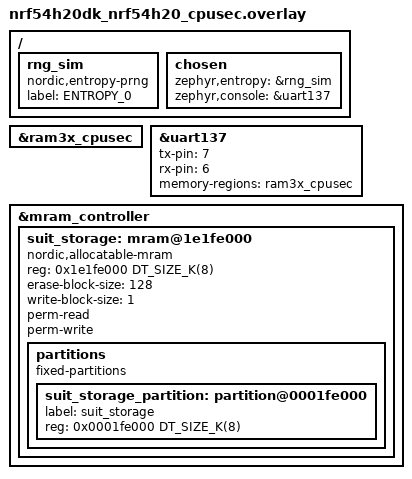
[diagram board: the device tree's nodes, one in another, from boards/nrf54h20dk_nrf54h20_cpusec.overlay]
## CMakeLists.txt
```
#
# Copyright (c) 2022 Nordic Semiconductor ASA
#
# SPDX-License-Identifier: Apache-2.0
#

cmake_minimum_required(VERSION 3.20.0)

find_package(Zephyr REQUIRED HINTS $ENV{ZEPHYR_BASE})

project(integration_test_suit_storage)
include(../cmake/test_template.cmake)

# Link with the CMake target, that includes SUIT platform internal APIs header
zephyr_library_link_libraries(suit_common)
```

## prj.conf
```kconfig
#
# Copyright (c) 2022 Nordic Semiconductor ASA
#
# SPDX-License-Identifier: Apache-2.0
#

CONFIG_ZTEST=y
CONFIG_SUIT=y
CONFIG_FLASH=y
CONFIG_SUIT_COMPONENT_MRAM=y
# It is required to reserve at least SUIT_PARTITION_ENVELOPE_SIZE
# on the stack for the test execution.
CONFIG_ZTEST_STACK_SIZE=4096
CONFIG_SUIT_PARTITION_N_ENVELOPES=3
```

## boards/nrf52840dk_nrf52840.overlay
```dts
/*
 * Copyright (c) 2022 Nordic Semiconductor ASA
 *
 * SPDX-License-Identifier: LicenseRef-Nordic-4-Clause
 */

 &flash0 {
	partitions {
		compatible = "fixed-partitions";
		#address-cells = <1>;
		#size-cells = <1>;

		/* Use the last 16KB of NVM as suit storage. */
		suit_storage_partition: partition@000fc000 {
			label = "suit_storage";
			reg = <0x000fc000 DT_SIZE_K(16)>;
		};
	};
};
```

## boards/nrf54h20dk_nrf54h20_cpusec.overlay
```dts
/*
 * Copyright (c) 2022 Nordic Semiconductor ASA
 *
 * SPDX-License-Identifier: LicenseRef-Nordic-5-Clause
 */

/ {
	rng_sim: rng_sim {
		status = "okay";
		compatible = "nordic,entropy-prng";
		label = "ENTROPY_0";
	};

	chosen {
		zephyr,entropy = &rng_sim;
		zephyr,console = &uart137;
	};
};

&ram3x_cpusec {
	status = "okay";
};

&uart137 {
	status = "okay";
	tx-pin = <7>;
	rx-pin = <6>;
	memory-regions = <&ram3x_cpusec>;
};

&mram_controller {
	suit_storage: mram@1e1fe000 {
		compatible = "nordic,allocatable-mram", "soc-nv-flash";
		reg = <0x1e1fe000 DT_SIZE_K(8)>;
		erase-block-size = <128>;
		write-block-size = <1>;
		perm-read;
		perm-write;
		partitions {
			compatible = "fixed-partitions";
			#address-cells = <1>;
			#size-cells = <1>;

			/* Use the last 8KB of NVM as suit storage. */
			suit_storage_partition: partition@0001fe000 {
				label = "suit_storage";
				reg = <0x0001fe000 DT_SIZE_K(8)>;
			};
		};
	};
};
```

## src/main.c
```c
/*
 * Copyright (c) 2022 Nordic Semiconductor ASA
 *
 * SPDX-License-Identifier: Apache-2.0
 */

#include <ztest.h>
#include <suit_storage.h>
#include <drivers/flash.h>
#include <zephyr/storage/flash_map.h>
#ifdef CONFIG_FLASH_SIMULATOR
#include <zephyr/drivers/flash/flash_simulator.h>
#endif /* CONFIG_FLASH_SIMULATOR */

/* Calculate absolute address from flash offset. */
#ifdef CONFIG_FLASH_SIMULATOR
static uint8_t *f_base_address = NULL;
#define FLASH_ADDRESS(address)  (f_base_address + address)
#else /* CONFIG_FLASH_SIMULATOR */
#define FLASH_ADDRESS(address)  (COND_CODE_1(DT_NODE_EXISTS(DT_NODELABEL(mram10)), \
	((address) + (DT_REG_ADDR(DT_NODELABEL(mram10)) & 0xEFFFFFFFUL)), \
	(address)))
#endif /* CONFIG_FLASH_SIMULATOR */

#define SUIT_STORAGE_ADDRESS     FLASH_ADDRESS(SUIT_STORAGE_OFFSET)
#define SUIT_STORAGE_OFFSET      FLASH_AREA_OFFSET(suit_storage)
#define SUIT_STORAGE_SIZE        FLASH_AREA_SIZE(suit_storage)

#define UPDATE_MAGIC_VALUE_AVAILABLE 0x5555AAAA
#define UPDATE_MAGIC_VALUE_CLEARED   0xAAAA5555
#define UPDATE_MAGIC_VALUE_EMPTY     0xFFFFFFFF

#define zassert_area_empty() \
	zassert_equal(*((uint32_t *)SUIT_STORAGE_ADDRESS), UPDATE_MAGIC_VALUE_EMPTY, \
		"Test precondition not met: area is not empty (0x%x).", \
		*((uint32_t *)SUIT_STORAGE_ADDRESS));

#define zassert_area_cleared() \
	zassert_equal(*((uint32_t *)SUIT_STORAGE_ADDRESS), UPDATE_MAGIC_VALUE_CLEARED, \
		"Test precondition not met: area is not cleared (0x%x).", \
		*((uint32_t *)SUIT_STORAGE_ADDRESS));

#define zassert_area_update_available() \
	zassert_equal(*((uint32_t *)SUIT_STORAGE_ADDRESS), UPDATE_MAGIC_VALUE_AVAILABLE, \
		"Test precondition not met: update is not available (0x%x).", \
		*((uint32_t *)SUIT_STORAGE_ADDRESS));


/** @brief SUIT envelope generated using the manifest/sample.json input file.
 *
 * @details This envelope contains 256-byte random numbers attached as an integrated
 *          payload and fetched directly into the memory-mapped region during install step.
 *          The envelope has been signed using the manifest/key_private.pem key.
 *
 * @note Please use the manifest/reenerate.sh script for regenerating payloads.
 */
static uint8_t manifest_buf[] = {
	0xD8, 0x6B, 0xA4, 0x02, 0x58, 0x73, 0x82, 0x58, 0x24, 0x82, 0x2F, 0x58, 0x20, 0x60, 0xE2,
	0x47, 0x5D, 0x53, 0x4C, 0xCB, 0x8B, 0x0F, 0x7E, 0x0B, 0xC1, 0x3E, 0x96, 0xB2, 0x99, 0xD6,
	0xF8, 0x41, 0xB1, 0x1B, 0x61, 0xDF, 0x88, 0xF3, 0xC1, 0x88, 0xC2, 0xBD, 0x5C, 0xE5, 0xF6,
	0x58, 0x4A, 0xD2, 0x84, 0x43, 0xA1, 0x01, 0x26, 0xA0, 0xF6, 0x58, 0x40, 0x09, 0xDB, 0x59,
	0xBF, 0xA2, 0xB1, 0x1F, 0x72, 0x26, 0xC4, 0xB9, 0x6F, 0xBA, 0x1E, 0xB5, 0x3F, 0x84, 0x15,
	0xAA, 0x6E, 0x7A, 0xE3, 0xA3, 0x8D, 0x0E, 0xCB, 0x29, 0x8A, 0x52, 0x2E, 0x5C, 0x9F, 0x7B,
	0x60, 0xEA, 0xEA, 0xA3, 0xDA, 0xCC, 0xF9, 0xC3, 0xE7, 0x99, 0x5B, 0x43, 0xBF, 0xA8, 0x1E,
	0x74, 0x20, 0xCE, 0x73, 0x8E, 0x8E, 0x2B, 0xF0, 0x2C, 0x32, 0xD3, 0x33, 0x04, 0x5D, 0x04,
	0xA8, 0x03, 0x58, 0xB8, 0xA7, 0x01, 0x01, 0x02, 0x01, 0x03, 0x58, 0x6D, 0xA2, 0x02, 0x81,
	0x84, 0x41, 0x4D, 0x41, 0x02, 0x45, 0x1A, 0x0E, 0x05, 0x40, 0x00, 0x45, 0x1A, 0x00, 0x05,
	0x60, 0x00, 0x04, 0x58, 0x56, 0x86, 0x14, 0xA4, 0x01, 0x50, 0x2B, 0xDC, 0x1C, 0x07, 0xE0,
	0xD1, 0x54, 0x84, 0xBE, 0x50, 0x63, 0x17, 0x4D, 0x5A, 0x74, 0xC3, 0x02, 0x50, 0x85, 0x20,
	0xEA, 0x9C, 0x51, 0x5E, 0x57, 0x79, 0x8B, 0x5F, 0xBD, 0xAD, 0x67, 0xDE, 0xC7, 0xD9, 0x03,
	0x58, 0x24, 0x82, 0x2F, 0x58, 0x20, 0x5F, 0xC3, 0x54, 0xBF, 0x8E, 0x8C, 0x50, 0xFB, 0x4F,
	0xBC, 0x2C, 0xFA, 0xEB, 0x04, 0x53, 0x41, 0xC9, 0x80, 0x6D, 0xEA, 0xBD, 0xCB, 0x41, 0x54,
	0xFB, 0x79, 0xCC, 0xA4, 0xF0, 0xC9, 0x8C, 0x12, 0x0E, 0x19, 0x01, 0x00, 0x01, 0x0F, 0x02,
	0x0F, 0x07, 0x43, 0x82, 0x03, 0x0F, 0x09, 0x43, 0x82, 0x17, 0x02, 0x11, 0x52, 0x86, 0x14,
	0xA1, 0x15, 0x69, 0x23, 0x66, 0x69, 0x6C, 0x65, 0x2E, 0x62, 0x69, 0x6E, 0x15, 0x02, 0x03,
	0x0F, 0x17, 0x82, 0x2F, 0x58, 0x20, 0xD1, 0x7B, 0x63, 0xF9, 0x8E, 0x13, 0x94, 0x5A, 0x60,
	0xA3, 0xC3, 0x55, 0x9B, 0xE3, 0xAE, 0x33, 0xF5, 0xF4, 0xA2, 0x0B, 0x7A, 0x23, 0x10, 0xA1,
	0x5C, 0x3A, 0xC9, 0xEC, 0xD9, 0xBD, 0x0D, 0xC7, 0x17, 0x58, 0x91, 0xA1, 0x84, 0x41, 0x4D,
	0x41, 0x02, 0x45, 0x1A, 0x0E, 0x05, 0x40, 0x00, 0x45, 0x1A, 0x00, 0x05, 0x60, 0x00, 0xA6,
	0x01, 0x78, 0x18, 0x4E, 0x6F, 0x72, 0x64, 0x69, 0x63, 0x20, 0x53, 0x65, 0x6D, 0x69, 0x63,
	0x6F, 0x6E, 0x64, 0x75, 0x63, 0x74, 0x6F, 0x72, 0x20, 0x41, 0x53, 0x41, 0x02, 0x6E, 0x6E,
	0x52, 0x46, 0x35, 0x34, 0x32, 0x30, 0x5F, 0x63, 0x70, 0x75, 0x61, 0x70, 0x70, 0x03, 0x6D,
	0x6E, 0x6F, 0x72, 0x64, 0x69, 0x63, 0x73, 0x65, 0x6D, 0x69, 0x2E, 0x6E, 0x6F, 0x04, 0x78,
	0x1C, 0x54, 0x68, 0x65, 0x20, 0x6E, 0x52, 0x46, 0x35, 0x34, 0x32, 0x30, 0x20, 0x61, 0x70,
	0x70, 0x6C, 0x69, 0x63, 0x61, 0x74, 0x69, 0x6F, 0x6E, 0x20, 0x63, 0x6F, 0x72, 0x65, 0x05,
	0x78, 0x1A, 0x53, 0x61, 0x6D, 0x70, 0x6C, 0x65, 0x20, 0x61, 0x70, 0x70, 0x6C, 0x69, 0x63,
	0x61, 0x74, 0x69, 0x6F, 0x6E, 0x20, 0x63, 0x6F, 0x72, 0x65, 0x20, 0x46, 0x57, 0x06, 0x66,
	0x76, 0x31, 0x2E, 0x30, 0x2E, 0x30, 0x69, 0x23, 0x66, 0x69, 0x6C, 0x65, 0x2E, 0x62, 0x69,
	0x6E, 0x59, 0x01, 0x00, 0xC7, 0x9C, 0xAB, 0x9D, 0xE8, 0x33, 0x7F, 0x30, 0x14, 0xEB, 0xAC,
	0x02, 0xAF, 0x26, 0x01, 0x5E, 0x80, 0x6D, 0x88, 0xA1, 0xDB, 0x11, 0xA7, 0x31, 0xDF, 0xA6,
	0xEC, 0xCB, 0x9B, 0x48, 0x0D, 0xC8, 0x34, 0x40, 0x6D, 0x30, 0x86, 0x7D, 0xE8, 0x1B, 0xEC,
	0x3C, 0xF5, 0x40, 0xD0, 0x48, 0x18, 0x82, 0x11, 0x9D, 0x7C, 0x3F, 0x6C, 0xE5, 0x8F, 0xF1,
	0xD3, 0x5D, 0xE1, 0x51, 0xF7, 0x6A, 0x0F, 0xAF, 0x0B, 0xBD, 0x4C, 0x5F, 0xA5, 0x34, 0x1A,
	0x66, 0xDB, 0x22, 0xEC, 0x63, 0xED, 0x4B, 0xAB, 0xC7, 0xC8, 0xF7, 0x59, 0xD8, 0xD6, 0x9E,
	0xEC, 0x71, 0x1B, 0x24, 0x20, 0xB9, 0xAE, 0xE1, 0x3B, 0xFC, 0xAE, 0xB8, 0x77, 0xAC, 0xA4,
	0x57, 0x34, 0x97, 0x84, 0x4F, 0x58, 0xD5, 0x68, 0x08, 0x6F, 0xE3, 0x9C, 0x7E, 0x1B, 0xD7,
	0x38, 0x22, 0x98, 0x48, 0xF8, 0x7A, 0x67, 0xB2, 0xD9, 0xAC, 0xC5, 0x34, 0xC1, 0x27, 0x82,
	0x8E, 0x42, 0x79, 0x84, 0x21, 0x37, 0x4C, 0x41, 0x4A, 0x0F, 0xE2, 0x7F, 0xA0, 0x6A, 0x19,
	0x13, 0x3D, 0x52, 0x22, 0x7F, 0xD6, 0x2F, 0x71, 0x12, 0x76, 0xAB, 0x25, 0x9C, 0xFC, 0x67,
	0x08, 0x03, 0x7C, 0xDB, 0x18, 0xE6, 0x45, 0xF8, 0x99, 0xC2, 0x9E, 0x2C, 0xE3, 0x9B, 0x25,
	0xA9, 0x7B, 0x09, 0xFF, 0x00, 0x57, 0x26, 0x08, 0x0A, 0x11, 0x42, 0xCF, 0x82, 0xA2, 0x6B,
	0x2A, 0x99, 0xF9, 0x71, 0x9D, 0x14, 0x19, 0x5C, 0x5C, 0x78, 0x31, 0x60, 0x42, 0x4A, 0x18,
	0x1F, 0xEC, 0x78, 0x6A, 0x9A, 0x7C, 0x4F, 0xCF, 0xE8, 0x5A, 0x29, 0x65, 0xCD, 0x01, 0x3B,
	0x6D, 0x53, 0xBB, 0xC6, 0xDB, 0xDA, 0xD5, 0x8F, 0xF7, 0xF4, 0xD9, 0xB9, 0x0A, 0x03, 0x4B,
	0xFF, 0x33, 0xAB, 0x3B, 0xC5, 0xAF, 0xD0, 0xB8, 0x2C, 0x0F, 0x6A, 0xA9, 0x11, 0xB0, 0xE8,
	0x57, 0x8C, 0x92, 0x53, 0x81,
};
static const size_t manifest_len = sizeof(manifest_buf);

/** @brief SUIT envelope, which was constructed by keeping only authentication wrapper and manifest
 *         from the previous envelope.
 */
static const uint8_t short_manifest_buf[] = {
	0xD8, 0x6B, 0xA2, 0x02, 0x58, 0x73, 0x82, 0x58, 0x24, 0x82, 0x2F, 0x58, 0x20, 0x60, 0xE2,
	0x47, 0x5D, 0x53, 0x4C, 0xCB, 0x8B, 0x0F, 0x7E, 0x0B, 0xC1, 0x3E, 0x96, 0xB2, 0x99, 0xD6,
	0xF8, 0x41, 0xB1, 0x1B, 0x61, 0xDF, 0x88, 0xF3, 0xC1, 0x88, 0xC2, 0xBD, 0x5C, 0xE5, 0xF6,
	0x58, 0x4A, 0xD2, 0x84, 0x43, 0xA1, 0x01, 0x26, 0xA0, 0xF6, 0x58, 0x40, 0x09, 0xDB, 0x59,
	0xBF, 0xA2, 0xB1, 0x1F, 0x72, 0x26, 0xC4, 0xB9, 0x6F, 0xBA, 0x1E, 0xB5, 0x3F, 0x84, 0x15,
	0xAA, 0x6E, 0x7A, 0xE3, 0xA3, 0x8D, 0x0E, 0xCB, 0x29, 0x8A, 0x52, 0x2E, 0x5C, 0x9F, 0x7B,
	0x60, 0xEA, 0xEA, 0xA3, 0xDA, 0xCC, 0xF9, 0xC3, 0xE7, 0x99, 0x5B, 0x43, 0xBF, 0xA8, 0x1E,
	0x74, 0x20, 0xCE, 0x73, 0x8E, 0x8E, 0x2B, 0xF0, 0x2C, 0x32, 0xD3, 0x33, 0x04, 0x5D, 0x04,
	0xA8, 0x03, 0x58, 0xB8, 0xA7, 0x01, 0x01, 0x02, 0x01, 0x03, 0x58, 0x6D, 0xA2, 0x02, 0x81,
	0x84, 0x41, 0x4D, 0x41, 0x02, 0x45, 0x1A, 0x0E, 0x05, 0x40, 0x00, 0x45, 0x1A, 0x00, 0x05,
	0x60, 0x00, 0x04, 0x58, 0x56, 0x86, 0x14, 0xA4, 0x01, 0x50, 0x2B, 0xDC, 0x1C, 0x07, 0xE0,
	0xD1, 0x54, 0x84, 0xBE, 0x50, 0x63, 0x17, 0x4D, 0x5A, 0x74, 0xC3, 0x02, 0x50, 0x85, 0x20,
	0xEA, 0x9C, 0x51, 0x5E, 0x57, 0x79, 0x8B, 0x5F, 0xBD, 0xAD, 0x67, 0xDE, 0xC7, 0xD9, 0x03,
	0x58, 0x24, 0x82, 0x2F, 0x58, 0x20, 0x5F, 0xC3, 0x54, 0xBF, 0x8E, 0x8C, 0x50, 0xFB, 0x4F,
	0xBC, 0x2C, 0xFA, 0xEB, 0x04, 0x53, 0x41, 0xC9, 0x80, 0x6D, 0xEA, 0xBD, 0xCB, 0x41, 0x54,
	0xFB, 0x79, 0xCC, 0xA4, 0xF0, 0xC9, 0x8C, 0x12, 0x0E, 0x19, 0x01, 0x00, 0x01, 0x0F, 0x02,
	0x0F, 0x07, 0x43, 0x82, 0x03, 0x0F, 0x09, 0x43, 0x82, 0x17, 0x02, 0x11, 0x52, 0x86, 0x14,
	0xA1, 0x15, 0x69, 0x23, 0x66, 0x69, 0x6C, 0x65, 0x2E, 0x62, 0x69, 0x6E, 0x15, 0x02, 0x03,
	0x0F, 0x17, 0x82, 0x2F, 0x58, 0x20, 0xD1, 0x7B, 0x63, 0xF9, 0x8E, 0x13, 0x94, 0x5A, 0x60,
	0xA3, 0xC3, 0x55, 0x9B, 0xE3, 0xAE, 0x33, 0xF5, 0xF4, 0xA2, 0x0B, 0x7A, 0x23, 0x10, 0xA1,
	0x5C, 0x3A, 0xC9, 0xEC, 0xD9, 0xBD, 0x0D, 0xC7,
};


static void test_setup_erased(void)
{
	uint32_t * storage = (uint32_t *)SUIT_STORAGE_ADDRESS;

	if (*storage == UPDATE_MAGIC_VALUE_EMPTY) {
		return;
	}

	/* Erase the area, to met the preconditions in the next test. */
	const struct device *fdev = DEVICE_DT_GET(DT_CHOSEN(zephyr_flash_controller));
	zassert_not_null(fdev, "Unable to find a driver to erase area");

	int rc = flash_erase(fdev, SUIT_STORAGE_OFFSET, SUIT_STORAGE_SIZE);
	zassert_equal(rc, 0, "Unable to erase memory before test execution");
}

static bool has_preconfigured_update(void)
{
	void * addr;
	size_t size;

	return ((suit_storage_update_get(&addr, &size) == 0) &&
	    (addr == (void *)0xCAFEFECA) &&
	    (size == 2044));
}

static void test_setup_valid_update(void)
{
	if (has_preconfigured_update()) {
		return;
	}

	/* Erase the area, to met the preconditions in the next test. */
	const struct device *fdev = DEVICE_DT_GET(DT_CHOSEN(zephyr_flash_controller));
	zassert_not_null(fdev, "Unable to find a driver to erase area");

	int rc = flash_erase(fdev, SUIT_STORAGE_OFFSET, SUIT_STORAGE_SIZE);
	zassert_equal(rc, 0, "Unable to erase memory before test execution");

	rc = suit_storage_update_set((void*)0xCAFEFECA, 2044);
	zassert_equal(rc, 0, "Unable to set correct DFU before test execution (0x%x, %d).",
		0xCAFEFECA, 2044);
}

static void test_suit_storage_init(void)
{
	size_t size;
	void *addr;
	int rc = 0;

	rc = suit_storage_install_envelope(0, manifest_buf, manifest_len);
	zassert_not_equal(rc, 0, "Envelope installed on uninitialized SUIT storage.");

	rc = suit_storage_installed_envelope_get(0, &addr, &size);
	zassert_not_equal(rc, 0, "Envelope received from uninitialized SUIT storage.");

	rc = suit_storage_update_clear();
	zassert_not_equal(rc, 0, "Update info cleared in uninitialized SUIT storage.");

	rc = suit_storage_update_set((void *)0xCAFECAFE, 1024);
	zassert_not_equal(rc, 0, "Update info set in uninitialized SUIT storage.");

	bool available = suit_storage_update_available();
	zassert_not_equal(available, true, "Update available on uninitialized SUIT storage.");

	rc = suit_storage_update_get(&addr, &size);
	zassert_not_equal(rc, 0, "Update info returned from uninitialized SUIT storage.");

	rc = suit_storage_init();
	zassert_equal(rc, 0, "Failed to initialize SUIT storage module (%d).", rc);
}

static void test_suit_storage_empty_update_available(void)
{
	bool available = suit_storage_update_available();

	zassert_area_empty();

	zassert_equal(available, false, "Storage is empty, but update availability is reported.");
}

static void test_suit_storage_empty_update_get(void)
{
	void *addr;
	size_t size;
	int rc = 0;

	zassert_area_empty();

	rc = suit_storage_update_get(NULL, NULL);
	zassert_not_equal(rc, 0, "Storage is empty, but update candidate was received");

	rc = suit_storage_update_get(NULL, &size);
	zassert_not_equal(rc, 0, "Storage is empty, but update candidate was received (%d)",
		size);

	rc = suit_storage_update_get(&addr, NULL);
	zassert_not_equal(rc, 0, "Storage is empty, but update candidate was received (0x%x)",
		addr);

	rc = suit_storage_update_get(&addr, &size);
	zassert_not_equal(rc, 0, "Storage is empty, but update candidate was received (0x%x, %d)",
		addr, size);
}

static void test_suit_storage_empty_update_clear(void)
{
	zassert_area_empty();

	int rc = suit_storage_update_clear();
	zassert_equal(rc, 0, "Unable to clear empty partition (%d)", rc);
}

static void test_suit_storage_update_set(void)
{
	void *addresses[] = {NULL, (void*)0xCAFEFECA};
	size_t sizes[] = {0, SUIT_STORAGE_SIZE + 1, SUIT_STORAGE_SIZE, 0x2048, 2044};
	int rc = 0;

	for (int addr_i = 0; addr_i < ARRAY_SIZE(addresses); addr_i++) {
		for (int size_i = 0; size_i < ARRAY_SIZE(sizes); size_i++) {
			void *addr = addresses[addr_i];
			size_t size = sizes[size_i];

			if ((addr != NULL) && (size > 0)) {
				rc = suit_storage_update_set(addr, size);
				zassert_equal(rc, 0,
					"Setting correct DFU partition failed (0x%x, %d).",
					addr, size);

				/* Verify set values */
				bool available = suit_storage_update_available();
				zassert_equal(available, true,
					"Set succeeded, but update availability is not reported.");

				void *read_addr;
				size_t read_size;
				rc = suit_storage_update_get(&read_addr, &read_size);
				zassert_equal(read_addr, addr,
					"Update set with wrong address (%p != %p)",
					read_addr, addr);
				zassert_equal(read_size, size,
					"Update set with wrong size (0x%x != 0x%x)",
					read_size, size);
			} else {
				rc = suit_storage_update_set(addr, size);
				zassert_not_equal(rc, 0,
					"Setting incorrect DFU partition should fail (0x%x, %d).",
					addr, size);

				bool available = suit_storage_update_available();
				zassert_equal(available, false,
					"Set succeeded, but update availability is reported.");
			}
		}
	}
}

static void test_suit_storage_empty_update_set(void)
{
	zassert_area_empty();

	test_suit_storage_update_set();
}

static void test_suit_storage_valid_update_clear(void)
{
	zassert_area_update_available();

	int rc = suit_storage_update_clear();
	zassert_equal(rc, 0, "Unable to clear empty partition (%d)", rc);
}

static void test_suit_storage_erased_update_clear(void)
{
	zassert_area_cleared();

	int rc = suit_storage_update_clear();
	zassert_equal(rc, 0, "Unable to clear empty partition (%d)", rc);
}

static void test_suit_storage_erased_update_set(void)
{
	zassert_area_cleared();

	test_suit_storage_update_set();
}

static void test_suit_storage_empty_envelopes(void)
{
	void *addr;
	size_t size;
	int rc = 0;

	for (size_t i = 0; i < CONFIG_SUIT_PARTITION_N_ENVELOPES; i++) {
		rc = suit_storage_installed_envelope_get(i, NULL, NULL);
		zassert_not_equal(rc, 0,
			"Arguments are incorrect, but %d envelope was received", i);

		rc = suit_storage_installed_envelope_get(i, NULL, &size);
		zassert_not_equal(rc, 0,
			"Arguments are incorrect, but %d envelope was received (%d)",
			i, size);

		rc = suit_storage_installed_envelope_get(i, &addr, NULL);
		zassert_not_equal(rc, 0,
			"Arguments are incorrect, but %d envelope was received (0x%x)",
			i, addr);

		rc = suit_storage_installed_envelope_get(i, &addr, &size);
		zassert_not_equal(rc, 0,
			"Suit storage is empty, but %d envelope was received (0x%x, %d)",
			i, addr, size);
	}
}

static void test_suit_storage_empty_envelope_get(void)
{
	int rc = 0;

	zassert_area_empty();

	test_suit_storage_empty_envelopes();

	rc = suit_storage_update_set((void*)0xCAFEFECA, 2044);
	zassert_equal(rc, 0,
		"Unable to set correct DFU before envelope content check (0x%x, %d).",
		0xCAFEFECA, 2044);
	test_suit_storage_empty_envelopes();

	rc = suit_storage_update_clear();
	zassert_equal(rc, 0,
		"Unable to clear empty partition before envelope content check (%d)", rc);
	test_suit_storage_empty_envelopes();
}

static void test_suit_storage_valid_envelope_set(void)
{
	uint8_t addr[CONFIG_SUIT_PARTITION_ENVELOPE_SIZE];
	size_t size = sizeof(addr);
	int rc = 0;

	zassert_equal(has_preconfigured_update(), true,
		"Storage do not contain a valid update condidate");

	for (size_t i = 0; i < CONFIG_SUIT_PARTITION_N_ENVELOPES; i++) {
		rc = suit_storage_install_envelope(i, NULL, 0);
		zassert_not_equal(rc, 0, "Arguments are incorrect, but %d envelope was set", i);
		zassert_not_equal(size, 0, "Arguments are incorrect, but %d envelope was set", i);

		rc = suit_storage_install_envelope(i, NULL, size);
		zassert_not_equal(rc, 0, "Arguments are incorrect, but %d envelope was set (%d)",
			i, size);

		rc = suit_storage_install_envelope(i, addr, 0);
		zassert_not_equal(rc, 0, "Arguments are incorrect, but %d envelope was set (0x%x)",
			i, addr);

		memset(addr, 0x11 * (i + 1), sizeof(addr));
		memcpy(addr, manifest_buf, manifest_len);

		rc = suit_storage_install_envelope(i, addr, size);
		zassert_equal(rc, 0,
			"Arguments are correct, but %d envelope was not set (0x%x, %d)",
			i, addr, size);

		zassert_equal(has_preconfigured_update(), true,
			"Storage do not contain a valid update condidate");

		for (size_t idx = 0; idx < CONFIG_SUIT_PARTITION_N_ENVELOPES; idx++) {
			uint8_t *read_addr;
			size_t read_size;

			rc = suit_storage_installed_envelope_get(idx, (void **)&read_addr, &read_size);
			if (idx <= i) {
				zassert_equal(rc, 0,
					"Unable to get %d envelope for verification (0x%x, %d)",
					idx, read_addr, read_size);
				zassert_equal(memcmp(read_addr, short_manifest_buf,
					sizeof(short_manifest_buf)), 0,
					"EUIT envelope %d corrupted", idx);
				zassert_equal(read_addr[sizeof(short_manifest_buf)],
					UPDATE_MAGIC_VALUE_EMPTY & 0xFF,
					"EUIT envelope %d overflowed", idx);
			} else  {
				zassert_not_equal(rc, 0,
					"Non-existing %d envelope retured (0x%x, %d)",
					idx, read_addr, read_size);
			}
		}
	}
}

static void test_suit_storage_invalid_indexes(void)
{
	uint8_t addr[CONFIG_SUIT_PARTITION_ENVELOPE_SIZE];
	size_t size = sizeof(addr);
	int rc = 0;

	zassert_equal(has_preconfigured_update(), true,
		"Storage do not contain a valid update condidate");

	for (size_t i = CONFIG_SUIT_PARTITION_N_ENVELOPES; i < 2 * CONFIG_SUIT_PARTITION_N_ENVELOPES; i++) {
		rc = suit_storage_install_envelope(i, NULL, 0);
		zassert_not_equal(rc, 0, "Arguments are incorrect, but %d envelope was set", i);
		zassert_not_equal(size, 0, "Arguments are incorrect, but %d envelope was set", i);

		rc = suit_storage_install_envelope(i, NULL, size);
		zassert_not_equal(rc, 0, "Arguments are incorrect, but %d envelope was set (%d)",
			i, size);

		rc = suit_storage_install_envelope(i, addr, 0);
		zassert_not_equal(rc, 0, "Arguments are incorrect, but %d envelope was set (0x%x)",
			i, addr);

		memset(addr, 0x11 * (i + 1), sizeof(addr));
		memcpy(addr, manifest_buf, manifest_len);

		rc = suit_storage_install_envelope(i, addr, size);
		zassert_not_equal(rc, 0,
			"Arguments are incorrect, but %d envelope was set (0x%x, %d)",
			i, addr, size);

		zassert_equal(has_preconfigured_update(), true,
			"Storage do not contain a valid update condidate");
	}
}


void test_main(void)
{
#ifdef CONFIG_FLASH_SIMULATOR
	static const struct device *fdev = DEVICE_DT_GET(DT_CHOSEN(zephyr_flash_controller));
	size_t f_size = 0;
	f_base_address = flash_simulator_get_memory(fdev, &f_size);
#endif /* CONFIG_FLASH_SIMULATOR */

	ztest_test_suite(test_suit_storage_update,
			 ztest_unit_test_setup_teardown(
				test_suit_storage_init,
				test_setup_erased, unit_test_noop),
			 ztest_unit_test_setup_teardown(
				test_suit_storage_empty_update_available,
				test_setup_erased, unit_test_noop),
			 ztest_unit_test_setup_teardown(
				test_suit_storage_empty_update_get,
				test_setup_erased, unit_test_noop),
			 ztest_unit_test_setup_teardown(
				test_suit_storage_empty_update_clear,
				test_setup_erased, unit_test_noop),
			 ztest_unit_test_setup_teardown(
				test_suit_storage_empty_update_set,
				test_setup_erased, unit_test_noop),
			 ztest_unit_test_setup_teardown(
				test_suit_storage_valid_update_clear,
				test_setup_valid_update, unit_test_noop),
			 ztest_unit_test(test_suit_storage_erased_update_clear),
			 ztest_unit_test(test_suit_storage_erased_update_set));

	ztest_test_suite(test_suit_storage_envelopes,
			 ztest_unit_test_setup_teardown(
				test_suit_storage_empty_envelope_get,
				test_setup_erased, unit_test_noop),
			 ztest_unit_test_setup_teardown(
				test_suit_storage_valid_envelope_set,
				test_setup_valid_update, unit_test_noop),
			 ztest_unit_test_setup_teardown(
				test_suit_storage_invalid_indexes,
				test_setup_valid_update, unit_test_noop));

	ztest_run_test_suite(test_suit_storage_update);
	ztest_run_test_suite(test_suit_storage_envelopes);
}
```
